# Cortex_M52 register map
Vendor: Arm Ltd.; Series: ARMv8.1-M Mainline; File version: 1.0.0
CPU: other r0p0, little endian, MPU, FPU, double-precision FPU, DSP, 8 interrupt priority bits
Registers are 32-bit, read-write, reset 0x0 unless marked. A register's access mark holds for its fields unless they carry their own. Offsets are from the block's base; [hi:lo] are bit positions; {n}, {i} and the like mark numbered series.

## NVIC — Nested Vectored Interrupt Controller: enable, pending, active and priority registers for the external interrupts (IRQ0 = exception 16) and the software trigger register. Bit k of register n refers to IRQ 32n+k.
Base 0xE000E100
Same registers: NVIC_NS 0xE002E100
{0x0+4i} ISER{i} (i=0..15) — Interrupt Set-Enable Register n (IRQ 32n..32n+31): write 1 to enable an interrupt, 0 has no effect; reads the enable state.
  [31:0] SETENA — Bit k: write 1 to enable IRQ 32n+k; reads 1 if enabled. Writing 0 has no effect.
{0x80+4i} ICER{i} (i=0..15) — Interrupt Clear-Enable Register n (IRQ 32n..32n+31): write 1 to disable an interrupt, 0 has no effect; reads the enable state.
  [31:0] CLRENA — Bit k: write 1 to disable IRQ 32n+k; reads 1 if enabled. Writing 0 has no effect.
{0x100+4i} ISPR{i} (i=0..15) — Interrupt Set-Pending Register n (IRQ 32n..32n+31): write 1 to set an interrupt pending; reads the pending state.
  [31:0] SETPEND — Bit k: write 1 to set IRQ 32n+k pending; reads 1 if pending.
{0x180+4i} ICPR{i} (i=0..15) — Interrupt Clear-Pending Register n (IRQ 32n..32n+31): write 1 to clear a pending interrupt; reads the pending state.
  [31:0] CLRPEND — Bit k: write 1 to clear IRQ 32n+k pending; reads 1 if pending.
{0x200+4i} IABR{i} (i=0..15) ro — Interrupt Active Bit Register n (IRQ 32n..32n+31): 1 = the interrupt handler is active (executing or preempted). Read-only.
  [31:0] ACTIVE — Bit k: 1 = the handler of IRQ 32n+k is active.
{0x280+4i} ITNS{i} (i=0..15) — Interrupt Target Non-secure Register n (Security Extension): 1 = IRQ 32n+k targets Non-secure state. Secure access only; RAZ/WI from Non-secure.
  [31:0] ITNS — Bit k: 1 = IRQ 32n+k targets Non-secure state, 0 = Secure.
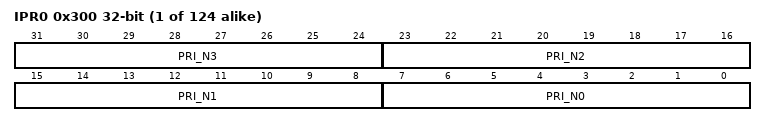
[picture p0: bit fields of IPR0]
{0x300+4i} IPR{i} (i=0..123) — Interrupt Priority Register n: one byte per interrupt, IRQ 4n+0 in bits [7:0] up to IRQ 4n+3 in [31:24]. Lower value = higher priority; only the top nvicPrioBits of each byte are implemented (ARMv6-M: 2, typical ARMv7-M: 3-4).
  [8n+7:8n] PRI_N{n} (n=0..3) — Priority of interrupt 4n+{n}. Only the top nvicPrioBits (implementation defined, 2 to 8) are implemented; the rest read as zero.
0xE00 STIR wo — Software Trigger Interrupt Register: writing an interrupt number sets that interrupt pending (like ISPR). Unprivileged writes need CCR.USERSETMPEND.
  [8:0] INTID — Interrupt number to set pending (0 = IRQ0, i.e. exception 16). Unprivileged writes are allowed when CCR.USERSETMPEND is 1.

## SAU — Security Attribution Unit (ARMv8-M Security Extension): defines which address ranges are Non-secure or Secure Non-secure-callable; everything else is Secure. Also holds the SecureFault status and address registers.
Base 0xE000EDD0
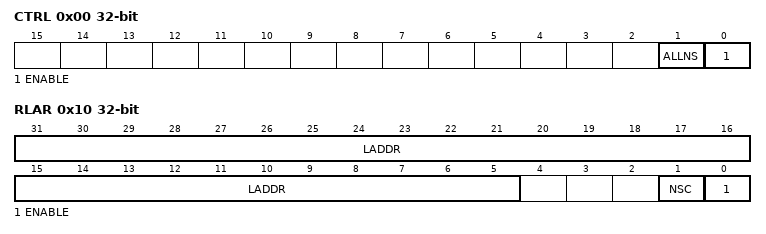
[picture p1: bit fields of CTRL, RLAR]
0x00 CTRL — SAU Control Register: enable, and what the memory map looks like while the SAU is disabled.
  [1] ALLNS — All Non-secure: with the SAU disabled, 1 = memory not marked Secure by the IDAU is Non-secure, 0 = all memory is Secure.
  [0] ENABLE — SAU enable. When 0 the whole address space is Secure (ALLNS = 0) or Non-secure (ALLNS = 1), subject to the IDAU.
0x04 TYPE ro — SAU Type Register: number of SAU regions implemented (0, 4 or 8 on Arm cores). Read-only.
  [7:0] SREGION — Number of SAU regions implemented (0, 4 or 8).
0x08 RNR — SAU Region Number Register: selects the region that RBAR and RLAR access.
  [7:0] REGION — Region selected for RBAR/RLAR accesses.
0x0C RBAR — SAU Region Base Address Register: start address (32-byte aligned) of the selected region.
  [31:5] BADDR — Region start address bits [31:5] (32-byte granularity).
0x10 RLAR — SAU Region Limit Address Register: inclusive end address, Non-secure-callable attribute and enable of the selected region.
  [31:5] LADDR — Region end address bits [31:5]; the low five bits are treated as 1 (inclusive limit).
  [1] NSC — 1 = the region is Secure and Non-secure-callable (holds the SG entry veneers); 0 = the region is Non-secure.
  [0] ENABLE — Region enable.
